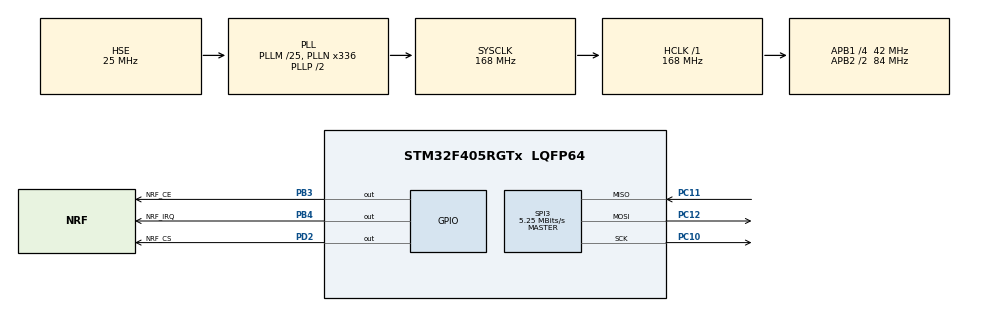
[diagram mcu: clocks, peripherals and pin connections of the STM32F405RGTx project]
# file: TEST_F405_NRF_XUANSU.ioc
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Mcu.Family=STM32F4
Mcu.Name=STM32F405RGTx
Mcu.Package=LQFP64
NVIC.PriorityGroup=NVIC_PRIORITYGROUP_4
PA13.Mode=Serial_Wire
PA13.Signal=SYS_JTMS-SWDIO
PA14.Mode=Serial_Wire
PA14.Signal=SYS_JTCK-SWCLK
PB3.GPIO_Label=NRF_CE
PB3.GPIO_PuPd=GPIO_PULLUP
PB3.GPIO_Speed=GPIO_SPEED_FREQ_HIGH
PB3.Signal=GPIO_Output
PB4.GPIO_Label=NRF_IRQ
PB4.GPIO_PuPd=GPIO_PULLUP
PB4.GPIO_Speed=GPIO_SPEED_FREQ_HIGH
PB4.Signal=GPIO_Output
PC10.Mode=Full_Duplex_Master
PC10.Signal=SPI3_SCK
PC11.Mode=Full_Duplex_Master
PC11.Signal=SPI3_MISO
PC12.Mode=Full_Duplex_Master
PC12.Signal=SPI3_MOSI
PD2.GPIO_Label=NRF_CS
PD2.GPIO_PuPd=GPIO_PULLUP
PD2.GPIO_Speed=GPIO_SPEED_FREQ_HIGH
PD2.Signal=GPIO_Output
PH0-OSC_IN.Mode=HSE-External-Oscillator
PH0-OSC_IN.Signal=RCC_OSC_IN
PH1-OSC_OUT.Mode=HSE-External-Oscillator
PH1-OSC_OUT.Signal=RCC_OSC_OUT
ProjectManager.HeapSize=0x200
ProjectManager.StackSize=0x400
ProjectManager.TargetToolchain=MDK-ARM V5.32
RCC.48MHZClocksFreq_Value=84000000
RCC.AHBFreq_Value=168000000
RCC.APB1CLKDivider=RCC_HCLK_DIV4
RCC.APB1Freq_Value=42000000
RCC.APB1TimFreq_Value=84000000
RCC.APB2CLKDivider=RCC_HCLK_DIV2
RCC.APB2Freq_Value=84000000
RCC.APB2TimFreq_Value=168000000
RCC.CortexFreq_Value=168000000
RCC.HCLKFreq_Value=168000000
RCC.HSE_VALUE=25000000
RCC.HSI_VALUE=16000000
RCC.LSE_VALUE=32768
RCC.PLLM=25
RCC.PLLN=336
RCC.PLLSourceVirtual=RCC_PLLSOURCE_HSE
RCC.SYSCLKFreq_VALUE=168000000
RCC.SYSCLKSource=RCC_SYSCLKSOURCE_PLLCLK
RCC.VCOOutputFreq_Value=336000000
SPI3.BaudRatePrescaler=SPI_BAUDRATEPRESCALER_8
SPI3.CalculateBaudRate=5.25 MBits/s
SPI3.Direction=SPI_DIRECTION_2LINES
SPI3.Mode=SPI_MODE_MASTER
SPI3.VirtualType=VM_MASTER
board=custom

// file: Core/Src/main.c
/* USER CODE BEGIN Header */
/**
  ******************************************************************************
  * @file           : main.c
  * @brief          : Main program body
  ******************************************************************************
  * @attention
  *
  * Copyright (c) 2023 STMicroelectronics.
  * All rights reserved.
  *
  * This software is licensed under terms that can be found in the LICENSE file
  * in the root directory of this software component.
  * If no LICENSE file comes with this software, it is provided AS-IS.
  *
  ******************************************************************************
  */
/* USER CODE END Header */
#include "main.h"
#include "spi.h"
#include "gpio.h"

/* USER CODE BEGIN Includes */
#include "nrf.h"
#include "my_robot.h"
#include "nrf_send.h"
/* USER CODE END Includes */

void SystemClock_Config(void);

int main(void)
{

  /* MCU Configuration--------------------------------------------------------*/

  /* Reset of all peripherals, Initializes the Flash interface and the Systick. */
  HAL_Init();

  /* Configure the system clock */
  SystemClock_Config();

  /* Initialize all configured peripherals */
  MX_GPIO_Init();
  MX_SPI3_Init();
  /* USER CODE BEGIN 2 */
		nrf_init();
		HAL_Delay(100);
  /* USER CODE END 2 */

  /* Infinite loop */
  while (1)
  {

    /* USER CODE BEGIN 3 */
		instruction_refresh();//接收手柄数据

		read_keys();//提取按键，遥感值

		check_and_sendACK();//响应

		HAL_Delay(1);
  }
  /* USER CODE END 3 */
}

void SystemClock_Config(void)
{
  RCC_OscInitTypeDef RCC_OscInitStruct = {0};
  RCC_ClkInitTypeDef RCC_ClkInitStruct = {0};

  /** Configure the main internal regulator output voltage
  */
  __HAL_RCC_PWR_CLK_ENABLE();
  __HAL_PWR_VOLTAGESCALING_CONFIG(PWR_REGULATOR_VOLTAGE_SCALE1);

  /** Initializes the RCC Oscillators according to the specified parameters
  * in the RCC_OscInitTypeDef structure.
  */
  RCC_OscInitStruct.OscillatorType = RCC_OSCILLATORTYPE_HSE;
  RCC_OscInitStruct.HSEState = RCC_HSE_ON;
  RCC_OscInitStruct.PLL.PLLState = RCC_PLL_ON;
  RCC_OscInitStruct.PLL.PLLSource = RCC_PLLSOURCE_HSE;
  RCC_OscInitStruct.PLL.PLLM = 25;
  RCC_OscInitStruct.PLL.PLLN = 336;
  RCC_OscInitStruct.PLL.PLLP = RCC_PLLP_DIV2;
  RCC_OscInitStruct.PLL.PLLQ = 4;
  if (HAL_RCC_OscConfig(&RCC_OscInitStruct) != HAL_OK)
  {
    Error_Handler();
  }

  /** Initializes the CPU, AHB and APB buses clocks
  */
  RCC_ClkInitStruct.ClockType = RCC_CLOCKTYPE_HCLK|RCC_CLOCKTYPE_SYSCLK
                              |RCC_CLOCKTYPE_PCLK1|RCC_CLOCKTYPE_PCLK2;
  RCC_ClkInitStruct.SYSCLKSource = RCC_SYSCLKSOURCE_PLLCLK;
  RCC_ClkInitStruct.AHBCLKDivider = RCC_SYSCLK_DIV1;
  RCC_ClkInitStruct.APB1CLKDivider = RCC_HCLK_DIV4;
  RCC_ClkInitStruct.APB2CLKDivider = RCC_HCLK_DIV2;

  if (HAL_RCC_ClockConfig(&RCC_ClkInitStruct, FLASH_LATENCY_5) != HAL_OK)
  {
    Error_Handler();
  }
}

void Error_Handler(void)
{
  __disable_irq();
  while (1)
  {
  }
}
